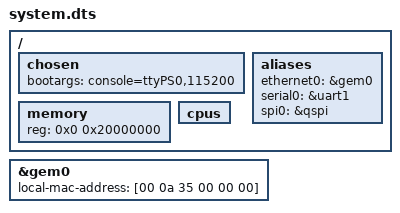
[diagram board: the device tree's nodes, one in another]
/*
 * CAUTION: This file is automatically generated by Xilinx.
 * Version:  
 * Today is: Thu Mar 23 11:33:24 2017
*/


/dts-v1/;
/include/ "pcw.dtsi"
/include/ "zynq-7000.dtsi"
/include/ "pl.dtsi"
/ {
	chosen {
		bootargs = "console=ttyPS0,115200";
	};
	aliases {
		ethernet0 = &gem0;
		serial0 = &uart1;
		spi0 = &qspi;
	};
	memory {
		device_type = "memory";
		reg = <0x0 0x20000000>;
	};
	cpus {
	};
};
&gem0 {
	local-mac-address = [00 0a 35 00 00 00];
};
